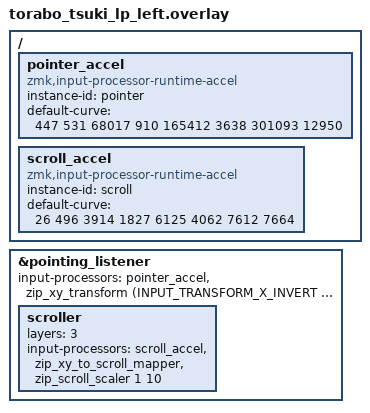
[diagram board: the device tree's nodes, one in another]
#include "torabo_tsuki_lp.dtsi"
#include <input/processors.dtsi>
#include <dt-bindings/zmk/input_transform.h>

/ {
    // 実行時設定可能な速度カーブ (Webアプリから変更可、初期値は従来の体感を再現)
    pointer_accel: pointer_accel {
        compatible = "zmk,input-processor-runtime-accel";
        #input-processor-cells = <0>;
        instance-id = "pointer";
        default-curve = <447 531 68017 910 165412 3638 301093 12950>;
    };

    scroll_accel: scroll_accel {
        compatible = "zmk,input-processor-runtime-accel";
        #input-processor-cells = <0>;
        instance-id = "scroll";
        default-curve = <26 496 3914 1827 6125 4062 7612 7664>;
    };
};

&pointing_listener {
    input-processors = <&pointer_accel>,
                       <&zip_xy_transform (INPUT_TRANSFORM_X_INVERT | INPUT_TRANSFORM_Y_INVERT)>;

    scroller {
        layers = <3>;
        input-processors = <&scroll_accel>,
                           <&zip_xy_to_scroll_mapper>,
                           <&zip_scroll_scaler 1 10>;
    };
};
